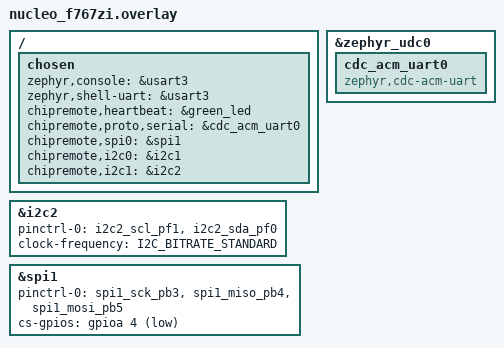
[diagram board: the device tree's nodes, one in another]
/ {
	chosen {
		zephyr,console = &usart3;
		zephyr,shell-uart = &usart3;
		chipremote,heartbeat = &green_led;
		chipremote,proto,serial = &cdc_acm_uart0;
		chipremote,spi0 = &spi1;
		chipremote,i2c0 = &i2c1;
		chipremote,i2c1 = &i2c2;
	};
};

&zephyr_udc0 {
	cdc_acm_uart0: cdc_acm_uart0 {
		compatible = "zephyr,cdc-acm-uart";
	};
};

&i2c2 {
	pinctrl-0 = < &i2c2_scl_pf1 &i2c2_sda_pf0 >;
	pinctrl-names = "default";
	status = "okay";
	clock-frequency = <I2C_BITRATE_STANDARD>;
};

&spi1 {
	/* Moving SPI1 to other pins to avoid the conflict with PA7 and
	 * the ethernet peripheral. This is on CN7, the ZIO header in the
	 * top right corner of the board, */
	pinctrl-0 = <&spi1_sck_pb3 &spi1_miso_pb4 &spi1_mosi_pb5>;
	pinctrl-names = "default";
	cs-gpios = <&gpioa 4 (GPIO_ACTIVE_LOW | GPIO_PULL_UP)>;
	status = "okay";
};
